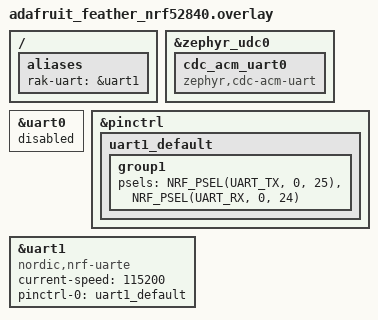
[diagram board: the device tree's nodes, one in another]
/ {
    aliases {
        rak-uart = &uart1;
    };
};

&zephyr_udc0 {
    status = "okay";
    cdc_acm_uart0: cdc_acm_uart0 {
        compatible = "zephyr,cdc-acm-uart";
    };
};

&uart0 {
    status = "disabled";
};

&pinctrl {
    uart1_default: uart1_default {
        group1 {
            psels = <NRF_PSEL(UART_TX, 0, 25)>, <NRF_PSEL(UART_RX, 0, 24)>;
        };
    };
};

&uart1 {
    compatible = "nordic,nrf-uarte";
    current-speed = <115200>;
    status = "okay";
    pinctrl-0 = <&uart1_default>;
    pinctrl-names = "default";
};
